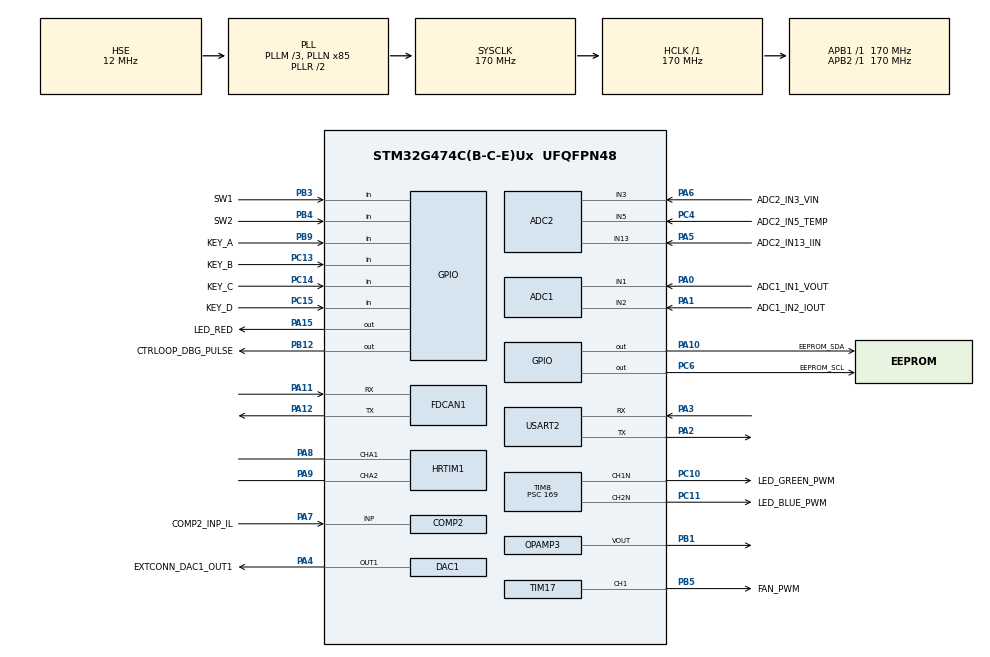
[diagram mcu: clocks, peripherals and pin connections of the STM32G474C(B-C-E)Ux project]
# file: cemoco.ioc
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ADC1.DMAContinuousRequests=DISABLE
ADC1.EOCSelection=ADC_EOC_SINGLE_CONV
ADC1.EnableInjectedConversion=ENABLE
ADC1.EnableInjectedOversampling=ENABLE
ADC1.EnableRegularConversion=DISABLE
ADC1.ExternalTrigInjecConv=ADC_EXTERNALTRIGINJEC_HRTIM_TRG2
ADC1.InjNumberOfConversion=2
ADC1.InjOversamplingRatio=ADC_OVERSAMPLING_RATIO_2
ADC1.InjOversamplingRightShift=ADC_RIGHTBITSHIFT_1
ADC1.InjectedChannel-5\#ChannelInjectedConversion=ADC_CHANNEL_1
ADC1.InjectedChannel-6\#ChannelInjectedConversion=ADC_CHANNEL_2
ADC1.InjectedOffsetNumber-5\#ChannelInjectedConversion=ADC_OFFSET_NONE
ADC1.InjectedOffsetNumber-6\#ChannelInjectedConversion=ADC_OFFSET_NONE
ADC1.InjectedRank-5\#ChannelInjectedConversion=1
ADC1.InjectedRank-6\#ChannelInjectedConversion=2
ADC1.InjectedSamplingTime-5\#ChannelInjectedConversion=ADC_SAMPLETIME_6CYCLES_5
ADC1.InjectedSamplingTime-6\#ChannelInjectedConversion=ADC_SAMPLETIME_6CYCLES_5
ADC1.Overrun=ADC_OVR_DATA_OVERWRITTEN
ADC1.OversamplingMode=DISABLE
ADC1.Rank1_Channel=ADC_CHANNEL_1
ADC1.Rank2_Channel=ADC_CHANNEL_2
ADC1.master=1
ADC2.Channel-0\#ChannelRegularConversion=ADC_CHANNEL_13
ADC2.Channel-1\#ChannelRegularConversion=ADC_CHANNEL_3
ADC2.Channel-2\#ChannelRegularConversion=ADC_CHANNEL_5
ADC2.DMAContinuousRequests=ENABLE
ADC2.EnableInjectedConversion=DISABLE
ADC2.EnableInjectedOversampling=ENABLE
ADC2.ExternalTrigConv=ADC_EXTERNALTRIG_HRTIM_TRG1
ADC2.NbrOfConversion=3
ADC2.NbrOfConversionFlag=1
ADC2.OffsetNumber-0\#ChannelRegularConversion=ADC_OFFSET_NONE
ADC2.OffsetNumber-1\#ChannelRegularConversion=ADC_OFFSET_NONE
ADC2.OffsetNumber-2\#ChannelRegularConversion=ADC_OFFSET_NONE
ADC2.Overrun=ADC_OVR_DATA_OVERWRITTEN
ADC2.Rank-0\#ChannelRegularConversion=1
ADC2.Rank-1\#ChannelRegularConversion=2
ADC2.Rank-2\#ChannelRegularConversion=3
ADC2.Rank1_Channel=ADC_CHANNEL_3
ADC2.SamplingTime-0\#ChannelRegularConversion=ADC_SAMPLETIME_12CYCLES_5
ADC2.SamplingTime-1\#ChannelRegularConversion=ADC_SAMPLETIME_12CYCLES_5
ADC2.SamplingTime-2\#ChannelRegularConversion=ADC_SAMPLETIME_12CYCLES_5
COMP2.Hysteresis=COMP_HYSTERESIS_NONE
COMP2.TriggerMode=COMP_TRIGGERMODE_EVENT_RISING
DAC3.DAC_Channel-DAC_OUT2_Int=DAC_CHANNEL_2
DAC3.DAC_Trigger2_OUT2-DAC_OUT2_Int=DAC_TRIGGER_HRTIM_STEP_TRG1
DAC3.DAC_Trigger_OUT2-DAC_OUT2_Int=DAC_TRIGGER_HRTIM_RST_TRG1
DAC3.ResetDataSawtooth2-DAC_OUT2_Int=4000
DAC3.StepDataSawtooth2-DAC_OUT2_Int=66
DAC3.WaveGeneration_OUT2-DAC_OUT2_Int=SawtoothWaveGenerate
Dma.ADC2.0.Direction=DMA_PERIPH_TO_MEMORY
Dma.ADC2.0.EventEnable=DISABLE
Dma.ADC2.0.Instance=DMA1_Channel2
Dma.ADC2.0.MemDataAlignment=DMA_MDATAALIGN_HALFWORD
Dma.ADC2.0.MemInc=DMA_MINC_ENABLE
Dma.ADC2.0.Mode=DMA_CIRCULAR
Dma.ADC2.0.PeriphDataAlignment=DMA_PDATAALIGN_HALFWORD
Dma.ADC2.0.PeriphInc=DMA_PINC_DISABLE
Dma.ADC2.0.Polarity=HAL_DMAMUX_REQ_GEN_RISING
Dma.ADC2.0.Priority=DMA_PRIORITY_LOW
Dma.ADC2.0.RequestNumber=1
Dma.ADC2.0.SignalID=NONE
Dma.ADC2.0.SyncEnable=DISABLE
Dma.ADC2.0.SyncPolarity=HAL_DMAMUX_SYNC_NO_EVENT
Dma.ADC2.0.SyncRequestNumber=1
Dma.ADC2.0.SyncSignalID=NONE
Dma.Request0=ADC2
FDCAN1.AutoRetransmission=ENABLE
FDCAN1.CalculateBaudRateNominal=500000
FDCAN1.CalculateTimeBitNominal=2000
FDCAN1.CalculateTimeQuantumNominal=100.0
FDCAN1.ExtFiltersNbr=2
FDCAN1.NominalPrescaler=17
FDCAN1.NominalTimeSeg1=16
FDCAN1.NominalTimeSeg2=3
FDCAN1.StdFiltersNbr=0
FDCAN1.TxFifoQueueMode=FDCAN_TX_FIFO_OPERATION
FREERTOS.Tasks01=defaultTask,24,128,StartDefaultTask,Default,NULL,Dynamic,NULL,NULL
FREERTOS.configENABLE_FPU=1
FREERTOS.configTOTAL_HEAP_SIZE=65536
HRTIM1.ADCTrigger1_Source1=HRTIM_ADCTRIGGEREVENT13_MASTER_CMP1
HRTIM1.ADCTrigger2_Source1=HRTIM_ADCTRIGGEREVENT24_MASTER_CMP1
HRTIM1.ADCTrigger_Id1=HRTIM_ADCTRIGGER_1
HRTIM1.ADCTrigger_Id2=HRTIM_ADCTRIGGER_2
HRTIM1.BURSTMODEPeriod=20
HRTIM1.BurstPreloadEnable=HRIM_BURSTMODEPRELOAD_ENABLED
HRTIM1.CaptureUnit1-Output_TA1TA2=__NULL
HRTIM1.CaptureUnit2-Output_TA1TA2=__NULL
HRTIM1.ClockSource=HRTIM_BURSTMODECLOCKSOURCE_TIMER_A
HRTIM1.CompareUnit1-MasterTimer=HRTIM_COMPAREUNIT_1
HRTIM1.CompareUnit1-Output_TA1TA2=HRTIM_COMPAREUNIT_1
HRTIM1.CompareUnit2-Output_TA1TA2=HRTIM_COMPAREUNIT_2
HRTIM1.CompareUnit3-Output_TA1TA2=HRTIM_COMPAREUNIT_3
HRTIM1.CompareUnit4-Output_TA1TA2=HRTIM_COMPAREUNIT_4
HRTIM1.CompareValue1-Output_TA1TA2=26112
HRTIM1.CompareValue2-Output_TA1TA2=250
HRTIM1.CompareValue3-Output_TA1TA2=543
HRTIM1.CompareValue4-Output_TA1TA2=1359
HRTIM1.Configuration_TA=Waveform
HRTIM1.DeadTimeInsertion-Output_TA1TA2=HRTIM_TIMDEADTIMEINSERTION_ENABLED
HRTIM1.Deadtimeconfig-Output_TA1TA2=HRTIM_TIMERINDEX_TIMER_A
HRTIM1.DualChannelDacEnableFake_TA-Output_TA1TA2=HRTIM_TIMER_DCDE_ENABLED_FAKE1
HRTIM1.Enable=HRTIM_BURSTMODECTL_ENABLED
HRTIM1.Event1-Output_TA1TA2=HRTIM_EVENT_1
HRTIM1.Event_EEV1=HRTIM_EVENT_1
HRTIM1.Event_EEV2=__NULL
HRTIM1.Event_EEV3=__NULL
HRTIM1.Event_EEV4=__NULL
HRTIM1.Event_EEV5=__NULL
HRTIM1.FallingValue-Output_TA1TA2=12
HRTIM1.FaultLevel1-Output_TA1TA2=HRTIM_OUTPUTFAULTLEVEL_INACTIVE
HRTIM1.FaultLevel2-Output_TA1TA2=HRTIM_OUTPUTFAULTLEVEL_INACTIVE
HRTIM1.Fault_Line1=__NULL
HRTIM1.Fault_Line4=__NULL
HRTIM1.Filter1-Output_TA1TA2=HRTIM_TIMEEVFLT_BLANKINGCMP4
HRTIM1.HRTIMInterruptResquests1=HRTIM_IT_NONE
HRTIM1.IdleDuration=20
HRTIM1.IdleMode1-Output_TA1TA2=HRTIM_OUTPUTIDLEMODE_IDLE
HRTIM1.IdleMode2-Output_TA1TA2=HRTIM_OUTPUTIDLEMODE_IDLE
HRTIM1.Mode=HRTIM_BURSTMODE_CONTINOUS
HRTIM1.NumberADCTriggerSource1=1
HRTIM1.NumberADCTriggerSource2=1
HRTIM1.NumberFaultEnable-Output_TA1TA2=0
HRTIM1.NumberResetSource1-Output_TA1TA2=2
HRTIM1.NumberResetSource2_TA=0
HRTIM1.NumberResetTrigger-Output_TA1TA2=1
HRTIM1.NumberSetSource1-Output_TA1TA2=1
HRTIM1.NumberUpdateTrigger-Output_TA1TA2=0
HRTIM1.Periode_MASTER=27200
HRTIM1.Periode_TA=27200
HRTIM1.Polarity2-Output_TA1TA2=HRTIM_OUTPUTPOLARITY_HIGH
HRTIM1.PreloadEnable-MasterTimer=HRTIM_PRELOAD_DISABLED
HRTIM1.PreloadEnable-Output_TA1TA2=HRTIM_PRELOAD_ENABLED
HRTIM1.PrescalerDead-Output_TA1TA2=HRTIM_TIMDEADTIME_PRESCALERRATIO_DIV1
HRTIM1.RepetitionCounter-Output_TA1TA2=0
HRTIM1.RepetitionUpdate-Output_TA1TA2=HRTIM_UPDATEONREPETITION_DISABLED
HRTIM1.ResetOutput1_Source1-Output_TA1TA2=HRTIM_OUTPUTSET_EEV_1
HRTIM1.ResetOutput1_Source2-Output_TA1TA2=HRTIM_OUTPUTRESET_TIMCMP1
HRTIM1.ResetTrigger1-Output_TA1TA2=HRTIM_TIMRESETTRIGGER_MASTER_PER
HRTIM1.ResetUpdate-Output_TA1TA2=HRTIM_TIMUPDATEONRESET_ENABLED
HRTIM1.RisingValue-Output_TA1TA2=12
HRTIM1.SetOutput1_Source1-Output_TA1TA2=HRTIM_OUTPUTSET_TIMCMP3
HRTIM1.UpDownMode-Output_TA1TA2=HRTIM_TIMERUPDOWNMODE_UP
HRTIM1.postscaler1=0
HRTIM1.postscaler2=0
Mcu.Family=STM32G4
Mcu.Name=STM32G474C(B-C-E)Ux
Mcu.Package=UFQFPN48
NVIC.ADC1_2_IRQn=true\:0\:0\:true\:false\:true\:false\:true\:true\:true
NVIC.FDCAN1_IT0_IRQn=true\:8\:0\:true\:false\:true\:true\:true\:true\:true
NVIC.HRTIM1_FLT_IRQn=true\:5\:0\:true\:false\:true\:false\:true\:true\:true
NVIC.PriorityGroup=NVIC_PRIORITYGROUP_4
NVIC.TIM7_DAC_IRQn=true\:15\:0\:true\:false\:true\:false\:false\:true\:true
NVIC.TimeBase=TIM7_DAC_IRQn
NVIC.TimeBaseIP=TIM7
PA0.GPIO_Label=ADC1_IN1_VOUT
PA0.Mode=IN1-Single-Ended
PA0.Signal=ADC1_IN1
PA1.GPIO_Label=ADC1_IN2_IOUT
PA1.Mode=IN2-Single-Ended
PA1.Signal=ADC1_IN2
PA10.GPIO_Label=EEPROM_SDA
PA10.GPIO_ModeDefaultOutputPP=GPIO_MODE_OUTPUT_OD
PA10.GPIO_PuPd=GPIO_NOPULL
PA10.Signal=GPIO_Output
PA11.Mode=FDCAN_Activate
PA11.Signal=FDCAN1_RX
PA12.Mode=FDCAN_Activate
PA12.Signal=FDCAN1_TX
PA13.GPIO_Label=SWDIO
PA13.Mode=Serial_Wire
PA13.Signal=SYS_JTMS-SWDIO
PA14.GPIO_Label=SWCLK
PA14.Mode=Serial_Wire
PA14.Signal=SYS_JTCK-SWCLK
PA15.GPIO_Label=LED_RED
PA15.GPIO_Speed=GPIO_SPEED_FREQ_VERY_HIGH
PA15.Signal=GPIO_Output
PA2.Mode=Asynchronous
PA2.Signal=USART2_TX
PA3.Mode=Asynchronous
PA3.Signal=USART2_RX
PA4.GPIO_Label=EXTCONN_DAC1_OUT1
PA4.Signal=COMP_DAC11_group
PA5.GPIO_Label=ADC2_IN13_IIN
PA5.Mode=IN13-Single-Ended
PA5.Signal=ADC2_IN13
PA6.GPIO_Label=ADC2_IN3_VIN
PA6.Mode=IN3-Single-Ended
PA6.Signal=ADC2_IN3
PA7.GPIO_Label=COMP2_INP_IL
PA7.Mode=INP
PA7.Signal=COMP2_INP
PA8.Mode=Output_TA1TA2
PA8.Signal=HRTIM1_CHA1
PA9.Mode=Output_TA1TA2
PA9.Signal=HRTIM1_CHA2
PB1.Mode=Follower-DAC_OUT2-INP
PB1.Signal=OPAMP3_VOUT
PB12.GPIO_Label=CTRLOOP_DBG_PULSE
PB12.Signal=GPIO_Output
PB3.GPIO_Label=SW1
PB3.Signal=GPIO_Input
PB4.GPIO_Label=SW2
PB4.Signal=GPIO_Input
PB5.GPIO_Label=FAN_PWM
PB5.Signal=S_TIM17_CH1
PB9.GPIO_Label=KEY_A
PB9.Signal=GPIO_Input
PC10.GPIO_Label=LED_GREEN_PWM
PC10.Mode=PWM Generation1 CH1N
PC10.Signal=TIM8_CH1N
PC11.GPIO_Label=LED_BLUE_PWM
PC11.Mode=PWM Generation2 CH2N
PC11.Signal=TIM8_CH2N
PC13.GPIO_Label=KEY_B
PC13.Signal=GPIO_Input
PC14-OSC32_IN.GPIO_Label=KEY_C
PC14-OSC32_IN.Signal=GPIO_Input
PC15-OSC32_OUT.GPIO_Label=KEY_D
PC15-OSC32_OUT.Signal=GPIO_Input
PC4.GPIO_Label=ADC2_IN5_TEMP
PC4.Mode=IN5-Single-Ended
PC4.Signal=ADC2_IN5
PC6.GPIO_Label=EEPROM_SCL
PC6.GPIO_ModeDefaultOutputPP=GPIO_MODE_OUTPUT_OD
PC6.GPIO_PuPd=GPIO_NOPULL
PC6.Signal=GPIO_Output
PF0-OSC_IN.Mode=HSE-External-Oscillator
PF0-OSC_IN.Signal=RCC_OSC_IN
PF1-OSC_OUT.Mode=HSE-External-Oscillator
PF1-OSC_OUT.Signal=RCC_OSC_OUT
ProjectManager.HeapSize=0x200
ProjectManager.StackSize=0x400
ProjectManager.TargetToolchain=CMake
RCC.ADC12Freq_Value=170000000
RCC.ADC345Freq_Value=170000000
RCC.AHBFreq_Value=170000000
RCC.APB1Freq_Value=170000000
RCC.APB1TimFreq_Value=170000000
RCC.APB2Freq_Value=170000000
RCC.APB2TimFreq_Value=170000000
RCC.CK48CLockSelection=RCC_USBCLKSOURCE_HSI48
RCC.CortexFreq_Value=170000000
RCC.EXTERNAL_CLOCK_VALUE=12288000
RCC.HCLKFreq_Value=170000000
RCC.HSE_VALUE=12000000
RCC.HSI48_VALUE=48000000
RCC.HSI_VALUE=16000000
RCC.LSE_VALUE=32768
RCC.PLLM=RCC_PLLM_DIV3
RCC.PLLN=85
RCC.PLLSourceVirtual=RCC_PLLSOURCE_HSE
RCC.SYSCLKFreq_VALUE=170000000
RCC.SYSCLKSource=RCC_SYSCLKSOURCE_PLLCLK
RCC.USBFreq_Value=48000000
RCC.VCOOutputFreq_Value=340000000
SH.COMP_DAC11_group.0=DAC1_OUT1,DAC_OUT1
SH.S_TIM17_CH1.0=TIM17_CH1,PWM Generation1 CH1
TIM17.Channel=TIM_CHANNEL_1
TIM17.PeriodNoDither=6799
TIM8.Channel-PWM\ Generation1\ CH1N=TIM_CHANNEL_1
TIM8.Channel-PWM\ Generation2\ CH2N=TIM_CHANNEL_2
TIM8.OCNPolarity_1=TIM_OCNPOLARITY_LOW
TIM8.OCNPolarity_2=TIM_OCNPOLARITY_LOW
TIM8.PeriodNoDither=99
TIM8.Prescaler=169
TIM8.RepetitionCounter=0
USART2.VirtualMode-Asynchronous=VM_ASYNC
VP_COMP2_VS_DAC3OUT2.Mode=INM_DAC3OUT2
VP_DAC3_VS_DACI2.Mode=DAC_OUT2_Int
VP_FREERTOS_VS_CMSIS_V2.Mode=CMSIS_V2
VP_HRTIM1_VS_hrtimMasterTimerNoOutput.Mode=MasterTimer
VP_SYS_VS_DBSignals.Mode=DisableDeadBatterySignals
VP_SYS_VS_tim7.Mode=TIM7
VP_SYS_V_VREFBUF.Mode=ExternalMode
VP_TIM17_VS_ClockSourceINT.Mode=Enable_Timer
board=custom

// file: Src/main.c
/* USER CODE BEGIN Header */
/**
  ******************************************************************************
  * @file           : main.c
  * @brief          : Main program body
  ******************************************************************************
  * @attention
  *
  * Copyright (c) 2025 STMicroelectronics.
  * All rights reserved.
  *
  * This software is licensed under terms that can be found in the LICENSE file
  * in the root directory of this software component.
  * If no LICENSE file comes with this software, it is provided AS-IS.
  *
  ******************************************************************************
  */
/* USER CODE END Header */
#include "main.h"
#include "cmsis_os.h"

/* USER CODE BEGIN Includes */

#include "app/app_main.h"

/* USER CODE END Includes */

COMP_HandleTypeDef hcomp2;

DAC_HandleTypeDef hdac1;
DAC_HandleTypeDef hdac3;

FDCAN_HandleTypeDef hfdcan1;

HRTIM_HandleTypeDef hhrtim1;

OPAMP_HandleTypeDef hopamp3;

TIM_HandleTypeDef htim8;
TIM_HandleTypeDef htim17;

UART_HandleTypeDef huart2;

/* Definitions for defaultTask */
osThreadId_t defaultTaskHandle;
const osThreadAttr_t defaultTask_attributes = {
  .name = "defaultTask",
  .priority = (osPriority_t) osPriorityNormal,
  .stack_size = 128 * 4
};

void SystemClock_Config(void);
static void MX_GPIO_Init(void);
static void MX_DMA_Init(void);
static void MX_ADC1_Init(void);
static void MX_ADC2_Init(void);
static void MX_HRTIM1_Init(void);
static void MX_USART2_UART_Init(void);
static void MX_COMP2_Init(void);
static void MX_DAC1_Init(void);
static void MX_DAC3_Init(void);
static void MX_FDCAN1_Init(void);
static void MX_TIM8_Init(void);
static void MX_OPAMP3_Init(void);
static void MX_TIM17_Init(void);
void StartDefaultTask(void *argument);

int main(void)
{

  /* MCU Configuration--------------------------------------------------------*/

  /* Reset of all peripherals, Initializes the Flash interface and the Systick. */
  HAL_Init();

  /* Configure the system clock */
  SystemClock_Config();

  /* Initialize all configured peripherals */
  MX_GPIO_Init();
  MX_DMA_Init();
  MX_ADC1_Init();
  MX_ADC2_Init();
  MX_HRTIM1_Init();
  MX_USART2_UART_Init();
  MX_COMP2_Init();
  MX_DAC1_Init();
  MX_DAC3_Init();
  MX_FDCAN1_Init();
  MX_TIM8_Init();
  MX_OPAMP3_Init();
  MX_TIM17_Init();
  /* USER CODE BEGIN 2 */

    struct app_context appctx = {
        .huart2 = &huart2,
        .hhrtim1 = &hhrtim1,
        .htim8 = &htim8,
        .hdac1 = &hdac1,
        .hdac3 = &hdac3,
        .hcomp2 = &hcomp2,
        .hopamp3 = &hopamp3,
        .hfdcan1 = &hfdcan1,
        .htim17 = &htim17
    };
    app_main(&appctx);

  /* USER CODE END 2 */

  /* Init scheduler */
  osKernelInitialize();

  /* Create the thread(s) */
  /* creation of defaultTask */
  defaultTaskHandle = osThreadNew(StartDefaultTask, NULL, &defaultTask_attributes);

  /* Start scheduler */
  osKernelStart();

  /* We should never get here as control is now taken by the scheduler */

  /* Infinite loop */
  while (1)
  {

  }
}

void SystemClock_Config(void)
{
  RCC_OscInitTypeDef RCC_OscInitStruct = {0};
  RCC_ClkInitTypeDef RCC_ClkInitStruct = {0};

  /** Configure the main internal regulator output voltage
  */
  HAL_PWREx_ControlVoltageScaling(PWR_REGULATOR_VOLTAGE_SCALE1_BOOST);

  /** Initializes the RCC Oscillators according to the specified parameters
  * in the RCC_OscInitTypeDef structure.
  */
  RCC_OscInitStruct.OscillatorType = RCC_OSCILLATORTYPE_HSE;
  RCC_OscInitStruct.HSEState = RCC_HSE_ON;
  RCC_OscInitStruct.PLL.PLLState = RCC_PLL_ON;
  RCC_OscInitStruct.PLL.PLLSource = RCC_PLLSOURCE_HSE;
  RCC_OscInitStruct.PLL.PLLM = RCC_PLLM_DIV3;
  RCC_OscInitStruct.PLL.PLLN = 85;
  RCC_OscInitStruct.PLL.PLLP = RCC_PLLP_DIV2;
  RCC_OscInitStruct.PLL.PLLQ = RCC_PLLQ_DIV2;
  RCC_OscInitStruct.PLL.PLLR = RCC_PLLR_DIV2;
  if (HAL_RCC_OscConfig(&RCC_OscInitStruct) != HAL_OK)
  {
    Error_Handler();
  }

  /** Initializes the CPU, AHB and APB buses clocks
  */
  RCC_ClkInitStruct.ClockType = RCC_CLOCKTYPE_HCLK|RCC_CLOCKTYPE_SYSCLK
                              |RCC_CLOCKTYPE_PCLK1|RCC_CLOCKTYPE_PCLK2;
  RCC_ClkInitStruct.SYSCLKSource = RCC_SYSCLKSOURCE_PLLCLK;
  RCC_ClkInitStruct.AHBCLKDivider = RCC_SYSCLK_DIV1;
  RCC_ClkInitStruct.APB1CLKDivider = RCC_HCLK_DIV1;
  RCC_ClkInitStruct.APB2CLKDivider = RCC_HCLK_DIV1;

  if (HAL_RCC_ClockConfig(&RCC_ClkInitStruct, FLASH_LATENCY_4) != HAL_OK)
  {
    Error_Handler();
  }
}

static void MX_ADC1_Init(void)
{

  LL_ADC_InitTypeDef ADC_InitStruct = {0};
  LL_ADC_REG_InitTypeDef ADC_REG_InitStruct = {0};
  LL_ADC_CommonInitTypeDef ADC_CommonInitStruct = {0};
  LL_ADC_INJ_InitTypeDef ADC_INJ_InitStruct = {0};

  LL_GPIO_InitTypeDef GPIO_InitStruct = {0};
  RCC_PeriphCLKInitTypeDef PeriphClkInit = {0};

  /** Initializes the peripherals clocks
  */
  PeriphClkInit.PeriphClockSelection = RCC_PERIPHCLK_ADC12;
  PeriphClkInit.Adc12ClockSelection = RCC_ADC12CLKSOURCE_SYSCLK;
  if (HAL_RCCEx_PeriphCLKConfig(&PeriphClkInit) != HAL_OK)
  {
    Error_Handler();
  }

  /* Peripheral clock enable */
  LL_AHB2_GRP1_EnableClock(LL_AHB2_GRP1_PERIPH_ADC12);

  LL_AHB2_GRP1_EnableClock(LL_AHB2_GRP1_PERIPH_GPIOA);
  /**ADC1 GPIO Configuration
  PA0   ------> ADC1_IN1
  PA1   ------> ADC1_IN2
  */
  GPIO_InitStruct.Pin = LL_GPIO_PIN_0;
  GPIO_InitStruct.Mode = LL_GPIO_MODE_ANALOG;
  GPIO_InitStruct.Pull = LL_GPIO_PULL_NO;
  LL_GPIO_Init(GPIOA, &GPIO_InitStruct);

  GPIO_InitStruct.Pin = LL_GPIO_PIN_1;
  GPIO_InitStruct.Mode = LL_GPIO_MODE_ANALOG;
  GPIO_InitStruct.Pull = LL_GPIO_PULL_NO;
  LL_GPIO_Init(GPIOA, &GPIO_InitStruct);

  /* ADC1 interrupt Init */
  NVIC_SetPriority(ADC1_2_IRQn, NVIC_EncodePriority(NVIC_GetPriorityGrouping(),0, 0));
  NVIC_EnableIRQ(ADC1_2_IRQn);

  /** Common config
  */
  ADC_InitStruct.Resolution = LL_ADC_RESOLUTION_12B;
  ADC_InitStruct.DataAlignment = LL_ADC_DATA_ALIGN_RIGHT;
  ADC_InitStruct.LowPowerMode = LL_ADC_LP_MODE_NONE;
  LL_ADC_Init(ADC1, &ADC_InitStruct);
  ADC_REG_InitStruct.SequencerLength = LL_ADC_REG_SEQ_SCAN_DISABLE;
  ADC_REG_InitStruct.SequencerDiscont = LL_ADC_REG_SEQ_DISCONT_DISABLE;
  ADC_REG_InitStruct.ContinuousMode = LL_ADC_REG_CONV_SINGLE;
  ADC_REG_InitStruct.DMATransfer = LL_ADC_REG_DMA_TRANSFER_NONE;
  ADC_REG_InitStruct.Overrun = LL_ADC_REG_OVR_DATA_OVERWRITTEN;
  LL_ADC_REG_Init(ADC1, &ADC_REG_InitStruct);
  LL_ADC_SetGainCompensation(ADC1, 0);
  LL_ADC_SetOverSamplingScope(ADC1, LL_ADC_OVS_GRP_INJECTED);
  ADC_CommonInitStruct.CommonClock = LL_ADC_CLOCK_SYNC_PCLK_DIV4;
  ADC_CommonInitStruct.Multimode = LL_ADC_MULTI_INDEPENDENT;
  LL_ADC_CommonInit(__LL_ADC_COMMON_INSTANCE(ADC1), &ADC_CommonInitStruct);
  ADC_INJ_InitStruct.TriggerSource = LL_ADC_INJ_TRIG_EXT_HRTIM_TRG2;
  ADC_INJ_InitStruct.SequencerLength = LL_ADC_INJ_SEQ_SCAN_ENABLE_2RANKS;
  ADC_INJ_InitStruct.SequencerDiscont = LL_ADC_INJ_SEQ_DISCONT_DISABLE;
  ADC_INJ_InitStruct.TrigAuto = LL_ADC_INJ_TRIG_INDEPENDENT;
  LL_ADC_INJ_Init(ADC1, &ADC_INJ_InitStruct);
  LL_ADC_INJ_SetQueueMode(ADC1, LL_ADC_INJ_QUEUE_DISABLE);
  LL_ADC_ConfigOverSamplingRatioShift(ADC1, LL_ADC_OVS_RATIO_2, LL_ADC_OVS_SHIFT_RIGHT_1);
  LL_ADC_INJ_SetTriggerEdge(ADC1, LL_ADC_INJ_TRIG_EXT_RISING);

  /* Disable ADC deep power down (enabled by default after reset state) */
  LL_ADC_DisableDeepPowerDown(ADC1);
  /* Enable ADC internal voltage regulator */
  LL_ADC_EnableInternalRegulator(ADC1);
  /* Delay for ADC internal voltage regulator stabilization. */
  /* Compute number of CPU cycles to wait for, from delay in us. */
  /* Note: Variable divided by 2 to compensate partially */
  /* CPU processing cycles (depends on compilation optimization). */
  /* Note: If system core clock frequency is below 200kHz, wait time */
  /* is only a few CPU processing cycles. */
  uint32_t wait_loop_index;
  wait_loop_index = ((LL_ADC_DELAY_INTERNAL_REGUL_STAB_US * (SystemCoreClock / (100000 * 2))) / 10);
  while(wait_loop_index != 0)
  {
    wait_loop_index--;
  }

  /** Configure Injected Channel
  */
  LL_ADC_INJ_SetSequencerRanks(ADC1, LL_ADC_INJ_RANK_1, LL_ADC_CHANNEL_1);
  LL_ADC_SetChannelSamplingTime(ADC1, LL_ADC_CHANNEL_1, LL_ADC_SAMPLINGTIME_6CYCLES_5);
  LL_ADC_SetChannelSingleDiff(ADC1, LL_ADC_CHANNEL_1, LL_ADC_SINGLE_ENDED);

  /** Configure Injected Channel
  */
  LL_ADC_INJ_SetSequencerRanks(ADC1, LL_ADC_INJ_RANK_2, LL_ADC_CHANNEL_2);
  LL_ADC_SetChannelSamplingTime(ADC1, LL_ADC_CHANNEL_2, LL_ADC_SAMPLINGTIME_6CYCLES_5);
  LL_ADC_SetChannelSingleDiff(ADC1, LL_ADC_CHANNEL_2, LL_ADC_SINGLE_ENDED);

}

static void MX_ADC2_Init(void)
{

  LL_ADC_InitTypeDef ADC_InitStruct = {0};
  LL_ADC_REG_InitTypeDef ADC_REG_InitStruct = {0};
  LL_ADC_INJ_InitTypeDef ADC_INJ_InitStruct = {0};

  LL_GPIO_InitTypeDef GPIO_InitStruct = {0};
  RCC_PeriphCLKInitTypeDef PeriphClkInit = {0};

  /** Initializes the peripherals clocks
  */
  PeriphClkInit.PeriphClockSelection = RCC_PERIPHCLK_ADC12;
  PeriphClkInit.Adc12ClockSelection = RCC_ADC12CLKSOURCE_SYSCLK;
  if (HAL_RCCEx_PeriphCLKConfig(&PeriphClkInit) != HAL_OK)
  {
    Error_Handler();
  }

  /* Peripheral clock enable */
  LL_AHB2_GRP1_EnableClock(LL_AHB2_GRP1_PERIPH_ADC12);

  LL_AHB2_GRP1_EnableClock(LL_AHB2_GRP1_PERIPH_GPIOA);
  LL_AHB2_GRP1_EnableClock(LL_AHB2_GRP1_PERIPH_GPIOC);
  /**ADC2 GPIO Configuration
  PA5   ------> ADC2_IN13
  PA6   ------> ADC2_IN3
  PC4   ------> ADC2_IN5
  */
  GPIO_InitStruct.Pin = LL_GPIO_PIN_5;
  GPIO_InitStruct.Mode = LL_GPIO_MODE_ANALOG;
  GPIO_InitStruct.Pull = LL_GPIO_PULL_NO;
  LL_GPIO_Init(GPIOA, &GPIO_InitStruct);

  GPIO_InitStruct.Pin = LL_GPIO_PIN_6;
  GPIO_InitStruct.Mode = LL_GPIO_MODE_ANALOG;
  GPIO_InitStruct.Pull = LL_GPIO_PULL_NO;
  LL_GPIO_Init(GPIOA, &GPIO_InitStruct);

  GPIO_InitStruct.Pin = LL_GPIO_PIN_4;
  GPIO_InitStruct.Mode = LL_GPIO_MODE_ANALOG;
  GPIO_InitStruct.Pull = LL_GPIO_PULL_NO;
  LL_GPIO_Init(GPIOC, &GPIO_InitStruct);

  /* ADC2 DMA Init */

  /* ADC2 Init */
  LL_DMA_SetPeriphRequest(DMA1, LL_DMA_CHANNEL_2, LL_DMAMUX_REQ_ADC2);

  LL_DMA_SetDataTransferDirection(DMA1, LL_DMA_CHANNEL_2, LL_DMA_DIRECTION_PERIPH_TO_MEMORY);

  LL_DMA_SetChannelPriorityLevel(DMA1, LL_DMA_CHANNEL_2, LL_DMA_PRIORITY_LOW);

  LL_DMA_SetMode(DMA1, LL_DMA_CHANNEL_2, LL_DMA_MODE_CIRCULAR);

  LL_DMA_SetPeriphIncMode(DMA1, LL_DMA_CHANNEL_2, LL_DMA_PERIPH_NOINCREMENT);

  LL_DMA_SetMemoryIncMode(DMA1, LL_DMA_CHANNEL_2, LL_DMA_MEMORY_INCREMENT);

  LL_DMA_SetPeriphSize(DMA1, LL_DMA_CHANNEL_2, LL_DMA_PDATAALIGN_HALFWORD);

  LL_DMA_SetMemorySize(DMA1, LL_DMA_CHANNEL_2, LL_DMA_MDATAALIGN_HALFWORD);

  /* ADC2 interrupt Init */
  NVIC_SetPriority(ADC1_2_IRQn, NVIC_EncodePriority(NVIC_GetPriorityGrouping(),0, 0));
  NVIC_EnableIRQ(ADC1_2_IRQn);

  /** Common config
  */
  ADC_InitStruct.Resolution = LL_ADC_RESOLUTION_12B;
  ADC_InitStruct.DataAlignment = LL_ADC_DATA_ALIGN_RIGHT;
  ADC_InitStruct.LowPowerMode = LL_ADC_LP_MODE_NONE;
  LL_ADC_Init(ADC2, &ADC_InitStruct);
  ADC_REG_InitStruct.TriggerSource = LL_ADC_REG_TRIG_EXT_HRTIM_TRG1;
  ADC_REG_InitStruct.SequencerLength = LL_ADC_REG_SEQ_SCAN_ENABLE_3RANKS;
  ADC_REG_InitStruct.SequencerDiscont = LL_ADC_REG_SEQ_DISCONT_DISABLE;
  ADC_REG_InitStruct.ContinuousMode = LL_ADC_REG_CONV_SINGLE;
  ADC_REG_InitStruct.DMATransfer = LL_ADC_REG_DMA_TRANSFER_UNLIMITED;
  ADC_REG_InitStruct.Overrun = LL_ADC_REG_OVR_DATA_OVERWRITTEN;
  LL_ADC_REG_Init(ADC2, &ADC_REG_InitStruct);
  LL_ADC_SetGainCompensation(ADC2, 0);
  LL_ADC_SetOverSamplingScope(ADC2, LL_ADC_OVS_GRP_INJECTED);
  ADC_INJ_InitStruct.SequencerDiscont = LL_ADC_INJ_SEQ_DISCONT_DISABLE;
  ADC_INJ_InitStruct.TrigAuto = LL_ADC_INJ_TRIG_INDEPENDENT;
  LL_ADC_INJ_Init(ADC2, &ADC_INJ_InitStruct);
  LL_ADC_REG_SetTriggerEdge(ADC2, LL_ADC_REG_TRIG_EXT_RISING);

  /* Disable ADC deep power down (enabled by default after reset state) */
  LL_ADC_DisableDeepPowerDown(ADC2);
  /* Enable ADC internal voltage regulator */
  LL_ADC_EnableInternalRegulator(ADC2);
  /* Delay for ADC internal voltage regulator stabilization. */
  /* Compute number of CPU cycles to wait for, from delay in us. */
  /* Note: Variable divided by 2 to compensate partially */
  /* CPU processing cycles (depends on compilation optimization). */
  /* Note: If system core clock frequency is below 200kHz, wait time */
  /* is only a few CPU processing cycles. */
  uint32_t wait_loop_index;
  wait_loop_index = ((LL_ADC_DELAY_INTERNAL_REGUL_STAB_US * (SystemCoreClock / (100000 * 2))) / 10);
  while(wait_loop_index != 0)
  {
    wait_loop_index--;
  }

  /** Configure Regular Channel
  */
  LL_ADC_REG_SetSequencerRanks(ADC2, LL_ADC_REG_RANK_1, LL_ADC_CHANNEL_13);
  LL_ADC_SetChannelSamplingTime(ADC2, LL_ADC_CHANNEL_13, LL_ADC_SAMPLINGTIME_12CYCLES_5);
  LL_ADC_SetChannelSingleDiff(ADC2, LL_ADC_CHANNEL_13, LL_ADC_SINGLE_ENDED);

  /** Configure Regular Channel
  */
  LL_ADC_REG_SetSequencerRanks(ADC2, LL_ADC_REG_RANK_2, LL_ADC_CHANNEL_3);
  LL_ADC_SetChannelSamplingTime(ADC2, LL_ADC_CHANNEL_3, LL_ADC_SAMPLINGTIME_12CYCLES_5);
  LL_ADC_SetChannelSingleDiff(ADC2, LL_ADC_CHANNEL_3, LL_ADC_SINGLE_ENDED);

  /** Configure Regular Channel
  */
  LL_ADC_REG_SetSequencerRanks(ADC2, LL_ADC_REG_RANK_3, LL_ADC_CHANNEL_5);
  LL_ADC_SetChannelSamplingTime(ADC2, LL_ADC_CHANNEL_5, LL_ADC_SAMPLINGTIME_12CYCLES_5);
  LL_ADC_SetChannelSingleDiff(ADC2, LL_ADC_CHANNEL_5, LL_ADC_SINGLE_ENDED);

}

static void MX_COMP2_Init(void)
{

  hcomp2.Instance = COMP2;
  hcomp2.Init.InputPlus = COMP_INPUT_PLUS_IO1;
  hcomp2.Init.InputMinus = COMP_INPUT_MINUS_DAC3_CH2;
  hcomp2.Init.OutputPol = COMP_OUTPUTPOL_NONINVERTED;
  hcomp2.Init.Hysteresis = COMP_HYSTERESIS_NONE;
  hcomp2.Init.BlankingSrce = COMP_BLANKINGSRC_NONE;
  hcomp2.Init.TriggerMode = COMP_TRIGGERMODE_EVENT_RISING;
  if (HAL_COMP_Init(&hcomp2) != HAL_OK)
  {
    Error_Handler();
  }

}

static void MX_DAC1_Init(void)
{

  DAC_ChannelConfTypeDef sConfig = {0};

  /** DAC Initialization
  */
  hdac1.Instance = DAC1;
  if (HAL_DAC_Init(&hdac1) != HAL_OK)
  {
    Error_Handler();
  }

  /** DAC channel OUT1 config
  */
  sConfig.DAC_HighFrequency = DAC_HIGH_FREQUENCY_INTERFACE_MODE_AUTOMATIC;
  sConfig.DAC_DMADoubleDataMode = DISABLE;
  sConfig.DAC_SignedFormat = DISABLE;
  sConfig.DAC_SampleAndHold = DAC_SAMPLEANDHOLD_DISABLE;
  sConfig.DAC_Trigger = DAC_TRIGGER_NONE;
  sConfig.DAC_Trigger2 = DAC_TRIGGER_NONE;
  sConfig.DAC_OutputBuffer = DAC_OUTPUTBUFFER_ENABLE;
  sConfig.DAC_ConnectOnChipPeripheral = DAC_CHIPCONNECT_EXTERNAL;
  sConfig.DAC_UserTrimming = DAC_TRIMMING_FACTORY;
  if (HAL_DAC_ConfigChannel(&hdac1, &sConfig, DAC_CHANNEL_1) != HAL_OK)
  {
    Error_Handler();
  }

}

static void MX_DAC3_Init(void)
{

  DAC_ChannelConfTypeDef sConfig = {0};

  /** DAC Initialization
  */
  hdac3.Instance = DAC3;
  if (HAL_DAC_Init(&hdac3) != HAL_OK)
  {
    Error_Handler();
  }

  /** DAC channel OUT2 config
  */
  sConfig.DAC_HighFrequency = DAC_HIGH_FREQUENCY_INTERFACE_MODE_AUTOMATIC;
  sConfig.DAC_DMADoubleDataMode = DISABLE;
  sConfig.DAC_SignedFormat = DISABLE;
  sConfig.DAC_SampleAndHold = DAC_SAMPLEANDHOLD_DISABLE;
  sConfig.DAC_Trigger = DAC_TRIGGER_HRTIM_RST_TRG1;
  sConfig.DAC_Trigger2 = DAC_TRIGGER_HRTIM_STEP_TRG1;
  sConfig.DAC_OutputBuffer = DAC_OUTPUTBUFFER_DISABLE;
  sConfig.DAC_ConnectOnChipPeripheral = DAC_CHIPCONNECT_INTERNAL;
  sConfig.DAC_UserTrimming = DAC_TRIMMING_FACTORY;
  if (HAL_DAC_ConfigChannel(&hdac3, &sConfig, DAC_CHANNEL_2) != HAL_OK)
  {
    Error_Handler();
  }

  /** Configure Sawtooth wave generation on DAC OUT2
  */
  if (HAL_DACEx_SawtoothWaveGenerate(&hdac3, DAC_CHANNEL_2, DAC_SAWTOOTH_POLARITY_DECREMENT, 4000, 66) != HAL_OK)
  {
    Error_Handler();
  }

}

static void MX_FDCAN1_Init(void)
{

  hfdcan1.Instance = FDCAN1;
  hfdcan1.Init.ClockDivider = FDCAN_CLOCK_DIV1;
  hfdcan1.Init.FrameFormat = FDCAN_FRAME_CLASSIC;
  hfdcan1.Init.Mode = FDCAN_MODE_NORMAL;
  hfdcan1.Init.AutoRetransmission = ENABLE;
  hfdcan1.Init.TransmitPause = DISABLE;
  hfdcan1.Init.ProtocolException = DISABLE;
  hfdcan1.Init.NominalPrescaler = 17;
  hfdcan1.Init.NominalSyncJumpWidth = 1;
  hfdcan1.Init.NominalTimeSeg1 = 16;
  hfdcan1.Init.NominalTimeSeg2 = 3;
  hfdcan1.Init.DataPrescaler = 1;
  hfdcan1.Init.DataSyncJumpWidth = 1;
  hfdcan1.Init.DataTimeSeg1 = 1;
  hfdcan1.Init.DataTimeSeg2 = 1;
  hfdcan1.Init.StdFiltersNbr = 0;
  hfdcan1.Init.ExtFiltersNbr = 2;
  hfdcan1.Init.TxFifoQueueMode = FDCAN_TX_FIFO_OPERATION;
  if (HAL_FDCAN_Init(&hfdcan1) != HAL_OK)
  {
    Error_Handler();
  }

}

static void MX_HRTIM1_Init(void)
{

  HRTIM_EventCfgTypeDef pEventCfg = {0};
  HRTIM_ADCTriggerCfgTypeDef pADCTriggerCfg = {0};
  HRTIM_BurstModeCfgTypeDef pBurstModeCfg = {0};
  HRTIM_TimeBaseCfgTypeDef pTimeBaseCfg = {0};
  HRTIM_TimerCfgTypeDef pTimerCfg = {0};
  HRTIM_CompareCfgTypeDef pCompareCfg = {0};
  HRTIM_TimerCtlTypeDef pTimerCtl = {0};
  HRTIM_TimerEventFilteringCfgTypeDef pTimerEventFilteringCfg = {0};
  HRTIM_DeadTimeCfgTypeDef pDeadTimeCfg = {0};
  HRTIM_OutputCfgTypeDef pOutputCfg = {0};

  hhrtim1.Instance = HRTIM1;
  hhrtim1.Init.HRTIMInterruptResquests = HRTIM_IT_NONE;
  hhrtim1.Init.SyncOptions = HRTIM_SYNCOPTION_NONE;
  if (HAL_HRTIM_Init(&hhrtim1) != HAL_OK)
  {
    Error_Handler();
  }
  if (HAL_HRTIM_DLLCalibrationStart(&hhrtim1, HRTIM_CALIBRATIONRATE_3) != HAL_OK)
  {
    Error_Handler();
  }
  if (HAL_HRTIM_PollForDLLCalibration(&hhrtim1, 10) != HAL_OK)
  {
    Error_Handler();
  }
  if (HAL_HRTIM_EventPrescalerConfig(&hhrtim1, HRTIM_EVENTPRESCALER_DIV1) != HAL_OK)
  {
    Error_Handler();
  }
  pEventCfg.Source = HRTIM_EEV1SRC_COMP2_OUT;
  pEventCfg.Polarity = HRTIM_EVENTPOLARITY_HIGH;
  pEventCfg.Sensitivity = HRTIM_EVENTSENSITIVITY_LEVEL;
  pEventCfg.FastMode = HRTIM_EVENTFASTMODE_DISABLE;
  if (HAL_HRTIM_EventConfig(&hhrtim1, HRTIM_EVENT_1, &pEventCfg) != HAL_OK)
  {
    Error_Handler();
  }
  pADCTriggerCfg.UpdateSource = HRTIM_ADCTRIGGERUPDATE_MASTER;
  pADCTriggerCfg.Trigger = HRTIM_ADCTRIGGEREVENT13_MASTER_CMP1;
  if (HAL_HRTIM_ADCTriggerConfig(&hhrtim1, HRTIM_ADCTRIGGER_1, &pADCTriggerCfg) != HAL_OK)
  {
    Error_Handler();
  }
  if (HAL_HRTIM_ADCPostScalerConfig(&hhrtim1, HRTIM_ADCTRIGGER_1, 0) != HAL_OK)
  {
    Error_Handler();
  }
  pADCTriggerCfg.Trigger = HRTIM_ADCTRIGGEREVENT24_MASTER_CMP1;
  if (HAL_HRTIM_ADCTriggerConfig(&hhrtim1, HRTIM_ADCTRIGGER_2, &pADCTriggerCfg) != HAL_OK)
  {
    Error_Handler();
  }
  if (HAL_HRTIM_ADCPostScalerConfig(&hhrtim1, HRTIM_ADCTRIGGER_2, 0) != HAL_OK)
  {
    Error_Handler();
  }
  pBurstModeCfg.Mode = HRTIM_BURSTMODE_CONTINOUS;
  pBurstModeCfg.ClockSource = HRTIM_BURSTMODECLOCKSOURCE_TIMER_A;
  pBurstModeCfg.Prescaler = HRTIM_BURSTMODEPRESCALER_DIV1;
  pBurstModeCfg.PreloadEnable = HRIM_BURSTMODEPRELOAD_ENABLED;
  pBurstModeCfg.Trigger = HRTIM_BURSTMODETRIGGER_NONE;
  pBurstModeCfg.IdleDuration = 20;
  pBurstModeCfg.Period = 20;
  if (HAL_HRTIM_BurstModeConfig(&hhrtim1, &pBurstModeCfg) != HAL_OK)
  {
    Error_Handler();
  }
  pTimeBaseCfg.Period = 27200;
  pTimeBaseCfg.RepetitionCounter = 0x00;
  pTimeBaseCfg.PrescalerRatio = HRTIM_PRESCALERRATIO_MUL32;
  pTimeBaseCfg.Mode = HRTIM_MODE_CONTINUOUS;
  if (HAL_HRTIM_TimeBaseConfig(&hhrtim1, HRTIM_TIMERINDEX_MASTER, &pTimeBaseCfg) != HAL_OK)
  {
    Error_Handler();
  }
  pTimerCfg.InterruptRequests = HRTIM_MASTER_IT_NONE;
  pTimerCfg.DMARequests = HRTIM_MASTER_DMA_NONE;
  pTimerCfg.DMASrcAddress = 0x0000;
  pTimerCfg.DMADstAddress = 0x0000;
  pTimerCfg.DMASize = 0x1;
  pTimerCfg.HalfModeEnable = HRTIM_HALFMODE_DISABLED;
  pTimerCfg.InterleavedMode = HRTIM_INTERLEAVED_MODE_DISABLED;
  pTimerCfg.StartOnSync = HRTIM_SYNCSTART_DISABLED;
  pTimerCfg.ResetOnSync = HRTIM_SYNCRESET_DISABLED;
  pTimerCfg.DACSynchro = HRTIM_DACSYNC_NONE;
  pTimerCfg.PreloadEnable = HRTIM_PRELOAD_DISABLED;
  pTimerCfg.UpdateGating = HRTIM_UPDATEGATING_INDEPENDENT;
  pTimerCfg.BurstMode = HRTIM_TIMERBURSTMODE_MAINTAINCLOCK;
  pTimerCfg.RepetitionUpdate = HRTIM_UPDATEONREPETITION_DISABLED;
  pTimerCfg.ReSyncUpdate = HRTIM_TIMERESYNC_UPDATE_UNCONDITIONAL;
  if (HAL_HRTIM_WaveformTimerConfig(&hhrtim1, HRTIM_TIMERINDEX_MASTER, &pTimerCfg) != HAL_OK)
  {
    Error_Handler();
  }
  pCompareCfg.CompareValue = 0xFFDF;
  if (HAL_HRTIM_WaveformCompareConfig(&hhrtim1, HRTIM_TIMERINDEX_MASTER, HRTIM_COMPAREUNIT_1, &pCompareCfg) != HAL_OK)
  {
    Error_Handler();
  }
  pTimeBaseCfg.RepetitionCounter = 0;
  if (HAL_HRTIM_TimeBaseConfig(&hhrtim1, HRTIM_TIMERINDEX_TIMER_A, &pTimeBaseCfg) != HAL_OK)
  {
    Error_Handler();
  }
  pTimerCtl.UpDownMode = HRTIM_TIMERUPDOWNMODE_UP;
  pTimerCtl.TrigHalf = HRTIM_TIMERTRIGHALF_DISABLED;
  pTimerCtl.GreaterCMP3 = HRTIM_TIMERGTCMP3_EQUAL;
  pTimerCtl.GreaterCMP1 = HRTIM_TIMERGTCMP1_EQUAL;
  pTimerCtl.DualChannelDacReset = HRTIM_TIMER_DCDR_COUNTER;
  pTimerCtl.DualChannelDacStep = HRTIM_TIMER_DCDS_CMP2;
  pTimerCtl.DualChannelDacEnable = HRTIM_TIMER_DCDE_ENABLED;
  if (HAL_HRTIM_WaveformTimerControl(&hhrtim1, HRTIM_TIMERINDEX_TIMER_A, &pTimerCtl) != HAL_OK)
  {
    Error_Handler();
  }
  pTimerCfg.InterruptRequests = HRTIM_TIM_IT_NONE;
  pTimerCfg.DMARequests = HRTIM_TIM_DMA_NONE;
  pTimerCfg.PreloadEnable = HRTIM_PRELOAD_ENABLED;
  pTimerCfg.PushPull = HRTIM_TIMPUSHPULLMODE_DISABLED;
  pTimerCfg.FaultEnable = HRTIM_TIMFAULTENABLE_NONE;
  pTimerCfg.FaultLock = HRTIM_TIMFAULTLOCK_READWRITE;
  pTimerCfg.DeadTimeInsertion = HRTIM_TIMDEADTIMEINSERTION_ENABLED;
  pTimerCfg.DelayedProtectionMode = HRTIM_TIMER_A_B_C_DELAYEDPROTECTION_DISABLED;
  pTimerCfg.UpdateTrigger = HRTIM_TIMUPDATETRIGGER_NONE;
  pTimerCfg.ResetTrigger = HRTIM_TIMRESETTRIGGER_MASTER_PER;
  pTimerCfg.ResetUpdate = HRTIM_TIMUPDATEONRESET_ENABLED;
  if (HAL_HRTIM_WaveformTimerConfig(&hhrtim1, HRTIM_TIMERINDEX_TIMER_A, &pTimerCfg) != HAL_OK)
  {
    Error_Handler();
  }
  pCompareCfg.CompareValue = 26112;
  if (HAL_HRTIM_WaveformCompareConfig(&hhrtim1, HRTIM_TIMERINDEX_TIMER_A, HRTIM_COMPAREUNIT_1, &pCompareCfg) != HAL_OK)
  {
    Error_Handler();
  }
  pCompareCfg.CompareValue = 250;
  pCompareCfg.AutoDelayedMode = HRTIM_AUTODELAYEDMODE_REGULAR;
  pCompareCfg.AutoDelayedTimeout = 0x0000;

  if (HAL_HRTIM_WaveformCompareConfig(&hhrtim1, HRTIM_TIMERINDEX_TIMER_A, HRTIM_COMPAREUNIT_2, &pCompareCfg) != HAL_OK)
  {
    Error_Handler();
  }
  pCompareCfg.CompareValue = 543;
  if (HAL_HRTIM_WaveformCompareConfig(&hhrtim1, HRTIM_TIMERINDEX_TIMER_A, HRTIM_COMPAREUNIT_3, &pCompareCfg) != HAL_OK)
  {
    Error_Handler();
  }
  pCompareCfg.CompareValue = 1359;

  if (HAL_HRTIM_WaveformCompareConfig(&hhrtim1, HRTIM_TIMERINDEX_TIMER_A, HRTIM_COMPAREUNIT_4, &pCompareCfg) != HAL_OK)
  {
    Error_Handler();
  }
  pTimerEventFilteringCfg.Filter = HRTIM_TIMEEVFLT_BLANKINGCMP4;
  pTimerEventFilteringCfg.Latch = HRTIM_TIMEVENTLATCH_DISABLED;
  if (HAL_HRTIM_TimerEventFilteringConfig(&hhrtim1, HRTIM_TIMERINDEX_TIMER_A, HRTIM_EVENT_1, &pTimerEventFilteringCfg) != HAL_OK)
  {
    Error_Handler();
  }
  pDeadTimeCfg.Prescaler = HRTIM_TIMDEADTIME_PRESCALERRATIO_DIV1;
  pDeadTimeCfg.RisingValue = 12;
  pDeadTimeCfg.RisingSign = HRTIM_TIMDEADTIME_RISINGSIGN_POSITIVE;
  pDeadTimeCfg.RisingLock = HRTIM_TIMDEADTIME_RISINGLOCK_WRITE;
  pDeadTimeCfg.RisingSignLock = HRTIM_TIMDEADTIME_RISINGSIGNLOCK_WRITE;
  pDeadTimeCfg.FallingValue = 12;
  pDeadTimeCfg.FallingSign = HRTIM_TIMDEADTIME_FALLINGSIGN_POSITIVE;
  pDeadTimeCfg.FallingLock = HRTIM_TIMDEADTIME_FALLINGLOCK_WRITE;
  pDeadTimeCfg.FallingSignLock = HRTIM_TIMDEADTIME_FALLINGSIGNLOCK_WRITE;
  if (HAL_HRTIM_DeadTimeConfig(&hhrtim1, HRTIM_TIMERINDEX_TIMER_A, &pDeadTimeCfg) != HAL_OK)
  {
    Error_Handler();
  }
  pOutputCfg.Polarity = HRTIM_OUTPUTPOLARITY_HIGH;
  pOutputCfg.SetSource = HRTIM_OUTPUTSET_TIMCMP3;
  pOutputCfg.ResetSource = HRTIM_OUTPUTSET_EEV_1|HRTIM_OUTPUTRESET_TIMCMP1;
  pOutputCfg.IdleMode = HRTIM_OUTPUTIDLEMODE_IDLE;
  pOutputCfg.IdleLevel = HRTIM_OUTPUTIDLELEVEL_INACTIVE;
  pOutputCfg.FaultLevel = HRTIM_OUTPUTFAULTLEVEL_INACTIVE;
  pOutputCfg.ChopperModeEnable = HRTIM_OUTPUTCHOPPERMODE_DISABLED;
  pOutputCfg.BurstModeEntryDelayed = HRTIM_OUTPUTBURSTMODEENTRY_REGULAR;
  if (HAL_HRTIM_WaveformOutputConfig(&hhrtim1, HRTIM_TIMERINDEX_TIMER_A, HRTIM_OUTPUT_TA1, &pOutputCfg) != HAL_OK)
  {
    Error_Handler();
  }
  pOutputCfg.SetSource = HRTIM_OUTPUTSET_NONE;
  pOutputCfg.ResetSource = HRTIM_OUTPUTRESET_NONE;
  if (HAL_HRTIM_WaveformOutputConfig(&hhrtim1, HRTIM_TIMERINDEX_TIMER_A, HRTIM_OUTPUT_TA2, &pOutputCfg) != HAL_OK)
  {
    Error_Handler();
  }
  HAL_HRTIM_MspPostInit(&hhrtim1);

}

static void MX_OPAMP3_Init(void)
{

  hopamp3.Instance = OPAMP3;
  hopamp3.Init.PowerMode = OPAMP_POWERMODE_NORMALSPEED;
  hopamp3.Init.Mode = OPAMP_FOLLOWER_MODE;
  hopamp3.Init.NonInvertingInput = OPAMP_NONINVERTINGINPUT_DAC;
  hopamp3.Init.InternalOutput = DISABLE;
  hopamp3.Init.TimerControlledMuxmode = OPAMP_TIMERCONTROLLEDMUXMODE_DISABLE;
  hopamp3.Init.UserTrimming = OPAMP_TRIMMING_FACTORY;
  if (HAL_OPAMP_Init(&hopamp3) != HAL_OK)
  {
    Error_Handler();
  }

}

static void MX_TIM8_Init(void)
{

  TIM_MasterConfigTypeDef sMasterConfig = {0};
  TIM_OC_InitTypeDef sConfigOC = {0};
  TIM_BreakDeadTimeConfigTypeDef sBreakDeadTimeConfig = {0};

  htim8.Instance = TIM8;
  htim8.Init.Prescaler = 169;
  htim8.Init.CounterMode = TIM_COUNTERMODE_UP;
  htim8.Init.Period = 99;
  htim8.Init.ClockDivision = TIM_CLOCKDIVISION_DIV1;
  htim8.Init.RepetitionCounter = 0;
  htim8.Init.AutoReloadPreload = TIM_AUTORELOAD_PRELOAD_DISABLE;
  if (HAL_TIM_PWM_Init(&htim8) != HAL_OK)
  {
    Error_Handler();
  }
  sMasterConfig.MasterOutputTrigger = TIM_TRGO_RESET;
  sMasterConfig.MasterOutputTrigger2 = TIM_TRGO2_RESET;
  sMasterConfig.MasterSlaveMode = TIM_MASTERSLAVEMODE_DISABLE;
  if (HAL_TIMEx_MasterConfigSynchronization(&htim8, &sMasterConfig) != HAL_OK)
  {
    Error_Handler();
  }
  sConfigOC.OCMode = TIM_OCMODE_PWM1;
  sConfigOC.Pulse = 0;
  sConfigOC.OCPolarity = TIM_OCPOLARITY_HIGH;
  sConfigOC.OCNPolarity = TIM_OCNPOLARITY_LOW;
  sConfigOC.OCFastMode = TIM_OCFAST_DISABLE;
  sConfigOC.OCIdleState = TIM_OCIDLESTATE_RESET;
  sConfigOC.OCNIdleState = TIM_OCNIDLESTATE_RESET;
  if (HAL_TIM_PWM_ConfigChannel(&htim8, &sConfigOC, TIM_CHANNEL_1) != HAL_OK)
  {
    Error_Handler();
  }
  if (HAL_TIM_PWM_ConfigChannel(&htim8, &sConfigOC, TIM_CHANNEL_2) != HAL_OK)
  {
    Error_Handler();
  }
  sBreakDeadTimeConfig.OffStateRunMode = TIM_OSSR_DISABLE;
  sBreakDeadTimeConfig.OffStateIDLEMode = TIM_OSSI_DISABLE;
  sBreakDeadTimeConfig.LockLevel = TIM_LOCKLEVEL_OFF;
  sBreakDeadTimeConfig.DeadTime = 0;
  sBreakDeadTimeConfig.BreakState = TIM_BREAK_DISABLE;
  sBreakDeadTimeConfig.BreakPolarity = TIM_BREAKPOLARITY_HIGH;
  sBreakDeadTimeConfig.BreakFilter = 0;
  sBreakDeadTimeConfig.BreakAFMode = TIM_BREAK_AFMODE_INPUT;
  sBreakDeadTimeConfig.Break2State = TIM_BREAK2_DISABLE;
  sBreakDeadTimeConfig.Break2Polarity = TIM_BREAK2POLARITY_HIGH;
  sBreakDeadTimeConfig.Break2Filter = 0;
  sBreakDeadTimeConfig.Break2AFMode = TIM_BREAK_AFMODE_INPUT;
  sBreakDeadTimeConfig.AutomaticOutput = TIM_AUTOMATICOUTPUT_DISABLE;
  if (HAL_TIMEx_ConfigBreakDeadTime(&htim8, &sBreakDeadTimeConfig) != HAL_OK)
  {
    Error_Handler();
  }
  HAL_TIM_MspPostInit(&htim8);

}

static void MX_TIM17_Init(void)
{

  TIM_OC_InitTypeDef sConfigOC = {0};
  TIM_BreakDeadTimeConfigTypeDef sBreakDeadTimeConfig = {0};

  htim17.Instance = TIM17;
  htim17.Init.Prescaler = 0;
  htim17.Init.CounterMode = TIM_COUNTERMODE_UP;
  htim17.Init.Period = 6799;
  htim17.Init.ClockDivision = TIM_CLOCKDIVISION_DIV1;
  htim17.Init.RepetitionCounter = 0;
  htim17.Init.AutoReloadPreload = TIM_AUTORELOAD_PRELOAD_DISABLE;
  if (HAL_TIM_Base_Init(&htim17) != HAL_OK)
  {
    Error_Handler();
  }
  if (HAL_TIM_PWM_Init(&htim17) != HAL_OK)
  {
    Error_Handler();
  }
  sConfigOC.OCMode = TIM_OCMODE_PWM1;
  sConfigOC.Pulse = 0;
  sConfigOC.OCPolarity = TIM_OCPOLARITY_HIGH;
  sConfigOC.OCNPolarity = TIM_OCNPOLARITY_HIGH;
  sConfigOC.OCFastMode = TIM_OCFAST_DISABLE;
  sConfigOC.OCIdleState = TIM_OCIDLESTATE_RESET;
  sConfigOC.OCNIdleState = TIM_OCNIDLESTATE_RESET;
  if (HAL_TIM_PWM_ConfigChannel(&htim17, &sConfigOC, TIM_CHANNEL_1) != HAL_OK)
  {
    Error_Handler();
  }
  sBreakDeadTimeConfig.OffStateRunMode = TIM_OSSR_DISABLE;
  sBreakDeadTimeConfig.OffStateIDLEMode = TIM_OSSI_DISABLE;
  sBreakDeadTimeConfig.LockLevel = TIM_LOCKLEVEL_OFF;
  sBreakDeadTimeConfig.DeadTime = 0;
  sBreakDeadTimeConfig.BreakState = TIM_BREAK_DISABLE;
  sBreakDeadTimeConfig.BreakPolarity = TIM_BREAKPOLARITY_HIGH;
  sBreakDeadTimeConfig.BreakFilter = 0;
  sBreakDeadTimeConfig.AutomaticOutput = TIM_AUTOMATICOUTPUT_DISABLE;
  if (HAL_TIMEx_ConfigBreakDeadTime(&htim17, &sBreakDeadTimeConfig) != HAL_OK)
  {
    Error_Handler();
  }
  HAL_TIM_MspPostInit(&htim17);

}

static void MX_USART2_UART_Init(void)
{

  huart2.Instance = USART2;
  huart2.Init.BaudRate = 115200;
  huart2.Init.WordLength = UART_WORDLENGTH_8B;
  huart2.Init.StopBits = UART_STOPBITS_1;
  huart2.Init.Parity = UART_PARITY_NONE;
  huart2.Init.Mode = UART_MODE_TX_RX;
  huart2.Init.HwFlowCtl = UART_HWCONTROL_NONE;
  huart2.Init.OverSampling = UART_OVERSAMPLING_16;
  huart2.Init.OneBitSampling = UART_ONE_BIT_SAMPLE_DISABLE;
  huart2.Init.ClockPrescaler = UART_PRESCALER_DIV1;
  huart2.AdvancedInit.AdvFeatureInit = UART_ADVFEATURE_NO_INIT;
  if (HAL_UART_Init(&huart2) != HAL_OK)
  {
    Error_Handler();
  }
  if (HAL_UARTEx_SetTxFifoThreshold(&huart2, UART_TXFIFO_THRESHOLD_1_8) != HAL_OK)
  {
    Error_Handler();
  }
  if (HAL_UARTEx_SetRxFifoThreshold(&huart2, UART_RXFIFO_THRESHOLD_1_8) != HAL_OK)
  {
    Error_Handler();
  }
  if (HAL_UARTEx_DisableFifoMode(&huart2) != HAL_OK)
  {
    Error_Handler();
  }

}

static void MX_DMA_Init(void)
{

  /* DMA controller clock enable */
  __HAL_RCC_DMAMUX1_CLK_ENABLE();
  __HAL_RCC_DMA1_CLK_ENABLE();

}

static void MX_GPIO_Init(void)
{
  GPIO_InitTypeDef GPIO_InitStruct = {0};

  /* GPIO Ports Clock Enable */
  __HAL_RCC_GPIOC_CLK_ENABLE();
  __HAL_RCC_GPIOF_CLK_ENABLE();
  __HAL_RCC_GPIOA_CLK_ENABLE();
  __HAL_RCC_GPIOB_CLK_ENABLE();

  /*Configure GPIO pin Output Level */
  HAL_GPIO_WritePin(CTRLOOP_DBG_PULSE_GPIO_Port, CTRLOOP_DBG_PULSE_Pin, GPIO_PIN_RESET);

  /*Configure GPIO pin Output Level */
  HAL_GPIO_WritePin(EEPROM_SCL_GPIO_Port, EEPROM_SCL_Pin, GPIO_PIN_RESET);

  /*Configure GPIO pin Output Level */
  HAL_GPIO_WritePin(GPIOA, EEPROM_SDA_Pin|LED_RED_Pin, GPIO_PIN_RESET);

  /*Configure GPIO pins : KEY_B_Pin KEY_C_Pin KEY_D_Pin */
  GPIO_InitStruct.Pin = KEY_B_Pin|KEY_C_Pin|KEY_D_Pin;
  GPIO_InitStruct.Mode = GPIO_MODE_INPUT;
  GPIO_InitStruct.Pull = GPIO_NOPULL;
  HAL_GPIO_Init(GPIOC, &GPIO_InitStruct);

  /*Configure GPIO pin : CTRLOOP_DBG_PULSE_Pin */
  GPIO_InitStruct.Pin = CTRLOOP_DBG_PULSE_Pin;
  GPIO_InitStruct.Mode = GPIO_MODE_OUTPUT_PP;
  GPIO_InitStruct.Pull = GPIO_NOPULL;
  GPIO_InitStruct.Speed = GPIO_SPEED_FREQ_LOW;
  HAL_GPIO_Init(CTRLOOP_DBG_PULSE_GPIO_Port, &GPIO_InitStruct);

  /*Configure GPIO pin : EEPROM_SCL_Pin */
  GPIO_InitStruct.Pin = EEPROM_SCL_Pin;
  GPIO_InitStruct.Mode = GPIO_MODE_OUTPUT_OD;
  GPIO_InitStruct.Pull = GPIO_NOPULL;
  GPIO_InitStruct.Speed = GPIO_SPEED_FREQ_LOW;
  HAL_GPIO_Init(EEPROM_SCL_GPIO_Port, &GPIO_InitStruct);

  /*Configure GPIO pin : EEPROM_SDA_Pin */
  GPIO_InitStruct.Pin = EEPROM_SDA_Pin;
  GPIO_InitStruct.Mode = GPIO_MODE_OUTPUT_OD;
  GPIO_InitStruct.Pull = GPIO_NOPULL;
  GPIO_InitStruct.Speed = GPIO_SPEED_FREQ_LOW;
  HAL_GPIO_Init(EEPROM_SDA_GPIO_Port, &GPIO_InitStruct);

  /*Configure GPIO pin : LED_RED_Pin */
  GPIO_InitStruct.Pin = LED_RED_Pin;
  GPIO_InitStruct.Mode = GPIO_MODE_OUTPUT_PP;
  GPIO_InitStruct.Pull = GPIO_NOPULL;
  GPIO_InitStruct.Speed = GPIO_SPEED_FREQ_VERY_HIGH;
  HAL_GPIO_Init(LED_RED_GPIO_Port, &GPIO_InitStruct);

  /*Configure GPIO pins : SW1_Pin SW2_Pin KEY_A_Pin */
  GPIO_InitStruct.Pin = SW1_Pin|SW2_Pin|KEY_A_Pin;
  GPIO_InitStruct.Mode = GPIO_MODE_INPUT;
  GPIO_InitStruct.Pull = GPIO_NOPULL;
  HAL_GPIO_Init(GPIOB, &GPIO_InitStruct);

}

void StartDefaultTask(void *argument)
{
  for(;;)
  {
    osDelay(1);
  }
}

void HAL_TIM_PeriodElapsedCallback(TIM_HandleTypeDef *htim)
{
  if (htim->Instance == TIM7)
  {
    HAL_IncTick();
  }
}

void Error_Handler(void)
{
  __disable_irq();
  while (1)
  {
  }
}
